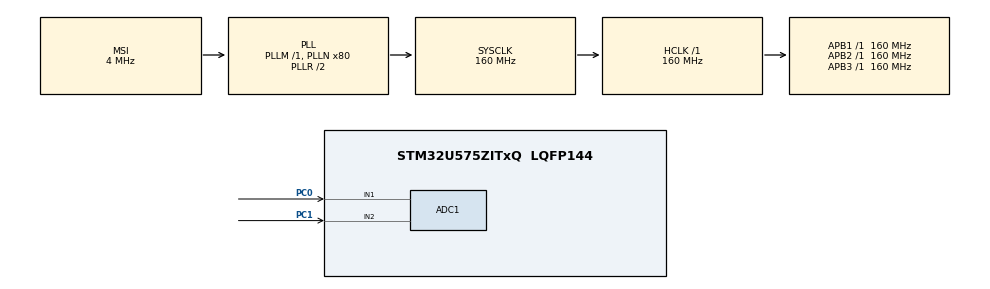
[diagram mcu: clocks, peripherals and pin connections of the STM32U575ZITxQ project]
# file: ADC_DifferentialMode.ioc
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ADC1.Channel-0\#ChannelRegularConversion=ADC_CHANNEL_1
ADC1.ClockPrescaler=ADC_CLOCK_ASYNC_DIV2
ADC1.ContinuousConvMode=ENABLE
ADC1.EnableRegularConversion=ENABLE
ADC1.NbrOfConversion=1
ADC1.NbrOfConversionFlag=1
ADC1.OffsetNumber-0\#ChannelRegularConversion=ADC_OFFSET_NONE
ADC1.Overrun=ADC_OVR_DATA_OVERWRITTEN
ADC1.Rank-0\#ChannelRegularConversion=1
ADC1.SamplingTime-0\#ChannelRegularConversion=ADC_SAMPLETIME_5CYCLE
ADC1.SingleDiff-0\#ChannelRegularConversion=ADC_DIFFERENTIAL_ENDED
ADC1.master=1
CORTEX_M33_NS.userName=CORTEX_M33
Mcu.Family=STM32U5
Mcu.Name=STM32U575ZITxQ
Mcu.Package=LQFP144
NVIC.PriorityGroup=NVIC_PRIORITYGROUP_4
PC0.Mode=IN1-Differential
PC0.Signal=ADC1_IN1
PC1.Mode=IN1-Differential
PC1.Signal=ADC1_IN2
PWR.PowerMode=PWR_SMPS_SUPPLY
ProjectManager.HeapSize=0x200
ProjectManager.StackSize=0x400
ProjectManager.TargetToolchain=EWARM V8.32
RCC.ADCFreq_Value=16000000
RCC.AHBFreq_Value=160000000
RCC.APB1Freq_Value=160000000
RCC.APB1TimFreq_Value=160000000
RCC.APB2Freq_Value=160000000
RCC.APB2TimFreq_Value=160000000
RCC.APB3Freq_Value=160000000
RCC.CortexFreq_Value=160000000
RCC.DACCLockSelectionVirtual=RCC_DAC1CLKSOURCE_LSI
RCC.DACCLockSelectionVirtualString=RCC_DAC1CLKSOURCE_LSI
RCC.EPOD_VALUE=4000000
RCC.HCLKFreq_Value=160000000
RCC.HSE_VALUE=16000000
RCC.HSI48_VALUE=48000000
RCC.HSI_VALUE=16000000
RCC.LSE_VALUE=32768
RCC.LSIDIV_VALUE=32000
RCC.MSI_VALUE=4000000
RCC.PLLN=80
RCC.SYSCLKFreq_VALUE=160000000
RCC.SYSCLKSource=RCC_SYSCLKSOURCE_PLLCLK
RCC.USBFreq_Value=48000000
RCC.VCOOutputFreq_Value=320000000
VP_ICACHE_VS_ICACHE.Mode=DirectMappedCache
VP_LPBAMQUEUE_VS_QUEUE.Mode=QUEUEMODE
VP_LPBAM_VS_SIG1.Mode=SmartRun
VP_LPBAM_VS_SIG4.Mode=LPDMA1
VP_PWR_VS_DBSignals.Mode=DisableDeadBatterySignals
VP_PWR_VS_LPOM.Mode=PowerOptimisation
VP_PWR_VS_SECSignals.Mode=Security/Privilege
board=custom

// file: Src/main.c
/* USER CODE BEGIN Header */
/**
  ******************************************************************************
  * @file           : main.c
  * @brief          : Main program body
  ******************************************************************************
  * @attention
  *
  * Copyright (c) 2021 STMicroelectronics.
  * All rights reserved.
  *
  * This software is licensed under terms that can be found in the LICENSE file
  * in the root directory of this software component.
  * If no LICENSE file comes with this software, it is provided AS-IS.
  *
  ******************************************************************************
  */
/* USER CODE END Header */
#include "main.h"

ADC_HandleTypeDef hadc1;

/* USER CODE BEGIN PV */
/* Converted value declaration */
uint32_t                 uhADCxConvertedData;
/* Input voltage declaration */
int32_t                  uhADCxConvertedData_Voltage_mVolt;
/* USER CODE END PV */

void SystemClock_Config(void);
static void SystemPower_Config(void);
static void MX_GPIO_Init(void);
static void MX_ICACHE_Init(void);
static void MX_ADC1_Init(void);

int main(void)
{

  /* USER CODE BEGIN 1 */
  /* STM32U5xx HAL library initialization:
       - Configure the Flash prefetch
       - Configure the Systick to generate an interrupt each 1 msec
       - Set NVIC Group Priority to 3
       - Low Level Initialization
     */
  /* USER CODE END 1 */

  /* MCU Configuration--------------------------------------------------------*/

  /* Reset of all peripherals, Initializes the Flash interface and the Systick. */
  HAL_Init();

  /* Configure the System Power */
  SystemPower_Config();

  /* Configure the system clock */
  SystemClock_Config();

  /* Initialize all configured peripherals */
  MX_GPIO_Init();
  MX_ICACHE_Init();
  MX_ADC1_Init();

  /* Infinite loop */
  /* USER CODE BEGIN WHILE */
  while (1)
  {
    if (HAL_ADC_PollForConversion(&hadc1, 10) != HAL_OK)
    {
      Error_Handler();
    }

    /* Read the converted value */
    uhADCxConvertedData = HAL_ADC_GetValue(&hadc1);

    /* Computation of ADC conversions raw data to physical values             */
    uhADCxConvertedData_Voltage_mVolt = (int32_t)((((uhADCxConvertedData) * 2UL) * VDDA_APPLI)
                                                   / __LL_ADC_DIGITAL_SCALE(hadc1.Instance, ADC_RESOLUTION_14B))
                                                 - (int32_t)(VDDA_APPLI);

    /* USER CODE END WHILE */

  }
}

void SystemClock_Config(void)
{
  RCC_OscInitTypeDef RCC_OscInitStruct = {0};
  RCC_ClkInitTypeDef RCC_ClkInitStruct = {0};

  /** Configure the main internal regulator output voltage
  */
  if (HAL_PWREx_ControlVoltageScaling(PWR_REGULATOR_VOLTAGE_SCALE1) != HAL_OK)
  {
    Error_Handler();
  }

  /** Initializes the CPU, AHB and APB buses clocks
  */
  RCC_OscInitStruct.OscillatorType = RCC_OSCILLATORTYPE_HSI|RCC_OSCILLATORTYPE_MSI;
  RCC_OscInitStruct.HSIState = RCC_HSI_ON;
  RCC_OscInitStruct.HSICalibrationValue = RCC_HSICALIBRATION_DEFAULT;
  RCC_OscInitStruct.MSIState = RCC_MSI_ON;
  RCC_OscInitStruct.MSICalibrationValue = RCC_MSICALIBRATION_DEFAULT;
  RCC_OscInitStruct.MSIClockRange = RCC_MSIRANGE_4;
  RCC_OscInitStruct.PLL.PLLState = RCC_PLL_ON;
  RCC_OscInitStruct.PLL.PLLSource = RCC_PLLSOURCE_MSI;
  RCC_OscInitStruct.PLL.PLLMBOOST = RCC_PLLMBOOST_DIV1;
  RCC_OscInitStruct.PLL.PLLM = 1;
  RCC_OscInitStruct.PLL.PLLN = 80;
  RCC_OscInitStruct.PLL.PLLP = 2;
  RCC_OscInitStruct.PLL.PLLQ = 2;
  RCC_OscInitStruct.PLL.PLLR = 2;
  RCC_OscInitStruct.PLL.PLLRGE = RCC_PLLVCIRANGE_0;
  RCC_OscInitStruct.PLL.PLLFRACN = 0;
  if (HAL_RCC_OscConfig(&RCC_OscInitStruct) != HAL_OK)
  {
    Error_Handler();
  }

  /** Initializes the CPU, AHB and APB buses clocks
  */
  RCC_ClkInitStruct.ClockType = RCC_CLOCKTYPE_HCLK|RCC_CLOCKTYPE_SYSCLK
                              |RCC_CLOCKTYPE_PCLK1|RCC_CLOCKTYPE_PCLK2
                              |RCC_CLOCKTYPE_PCLK3;
  RCC_ClkInitStruct.SYSCLKSource = RCC_SYSCLKSOURCE_PLLCLK;
  RCC_ClkInitStruct.AHBCLKDivider = RCC_SYSCLK_DIV1;
  RCC_ClkInitStruct.APB1CLKDivider = RCC_HCLK_DIV1;
  RCC_ClkInitStruct.APB2CLKDivider = RCC_HCLK_DIV1;
  RCC_ClkInitStruct.APB3CLKDivider = RCC_HCLK_DIV1;

  if (HAL_RCC_ClockConfig(&RCC_ClkInitStruct, FLASH_LATENCY_4) != HAL_OK)
  {
    Error_Handler();
  }
}

/**
  * @brief Power Configuration
  * @retval None
  */
static void SystemPower_Config(void)
{

  /*
   * Disable the internal Pull-Up in Dead Battery pins of UCPD peripheral
   */
  HAL_PWREx_DisableUCPDDeadBattery();

  /*
   * Switch to SMPS regulator instead of LDO
   */
  if (HAL_PWREx_ConfigSupply(PWR_SMPS_SUPPLY) != HAL_OK)
  {
    Error_Handler();
  }
}

static void MX_ADC1_Init(void)
{

  ADC_ChannelConfTypeDef sConfig = {0};

  /** Common config
  */
  hadc1.Instance = ADC1;
  hadc1.Init.ClockPrescaler = ADC_CLOCK_ASYNC_DIV2;
  hadc1.Init.Resolution = ADC_RESOLUTION_14B;
  hadc1.Init.GainCompensation = 0;
  hadc1.Init.ScanConvMode = ADC_SCAN_DISABLE;
  hadc1.Init.EOCSelection = ADC_EOC_SINGLE_CONV;
  hadc1.Init.LowPowerAutoWait = DISABLE;
  hadc1.Init.ContinuousConvMode = ENABLE;
  hadc1.Init.NbrOfConversion = 1;
  hadc1.Init.DiscontinuousConvMode = DISABLE;
  hadc1.Init.ExternalTrigConv = ADC_SOFTWARE_START;
  hadc1.Init.ExternalTrigConvEdge = ADC_EXTERNALTRIGCONVEDGE_NONE;
  hadc1.Init.DMAContinuousRequests = DISABLE;
  hadc1.Init.TriggerFrequencyMode = ADC_TRIGGER_FREQ_HIGH;
  hadc1.Init.Overrun = ADC_OVR_DATA_OVERWRITTEN;
  hadc1.Init.LeftBitShift = ADC_LEFTBITSHIFT_NONE;
  hadc1.Init.ConversionDataManagement = ADC_CONVERSIONDATA_DR;
  hadc1.Init.OversamplingMode = DISABLE;
  if (HAL_ADC_Init(&hadc1) != HAL_OK)
  {
    Error_Handler();
  }

  /** Configure Regular Channel
  */
  sConfig.Channel = ADC_CHANNEL_1;
  sConfig.Rank = ADC_REGULAR_RANK_1;
  sConfig.SamplingTime = ADC_SAMPLETIME_5CYCLE;
  sConfig.SingleDiff = ADC_DIFFERENTIAL_ENDED;
  sConfig.OffsetNumber = ADC_OFFSET_NONE;
  sConfig.Offset = 0;
  if (HAL_ADC_ConfigChannel(&hadc1, &sConfig) != HAL_OK)
  {
    Error_Handler();
  }
  /* USER CODE BEGIN ADC1_Init 2 */
  if (HAL_ADCEx_Calibration_Start(&hadc1, ADC_CALIB_OFFSET, ADC_DIFFERENTIAL_ENDED) != HAL_OK)
  {
    Error_Handler();
  }

  if (HAL_ADC_Start(&hadc1) != HAL_OK)
  {
    Error_Handler();
  }
  /* USER CODE END ADC1_Init 2 */

}

static void MX_ICACHE_Init(void)
{

  /** Enable instruction cache in 1-way (direct mapped cache)
  */
  if (HAL_ICACHE_ConfigAssociativityMode(ICACHE_1WAY) != HAL_OK)
  {
    Error_Handler();
  }
  if (HAL_ICACHE_Enable() != HAL_OK)
  {
    Error_Handler();
  }

}

static void MX_GPIO_Init(void)
{

  /* GPIO Ports Clock Enable */
  __HAL_RCC_GPIOC_CLK_ENABLE();

}

void Error_Handler(void)
{
  __disable_irq();
  while (1)
  {
  }
}
